# AUX_AIODIO register map
Vendor: Texas Instruments
Peripheral module from a debugger description file (folder CC2652).
Registers are 32-bit, access per field, reset 0x0 unless marked. A register's access mark holds for its fields unless they carry their own. Offsets are as the file gives them; lines under a group give offsets from that group; [hi:lo] are bit positions; {n}, {i} and the like mark numbered series; 'fields as' and 'values as' point back to an identical list; <NAME> marks a mode.

## AUX_AIODIO — AUX Analog Digital Input Output Controller (AUX_AIODIO) controls the general purpose input output pins of the AUX domain. These pins are referenced as AUXIO and can: - be connected to analog AUX modules, such as comparators and ADC. - be used by AUX_SCE. - connect to AUX_SPIM SCLK, MISO and MOSI signals. - connect to the asynchronous AUX event bus. Enabled digital inputs are synchronized at SCE clock rate. Note that the IO mapping in the AUX domain is different from the IO mapping in the MCU domain. This means that AUXIO[n] does not map to DIO[n]. AUXIO-DIO remapping is handled by Sensor Controller Studio.
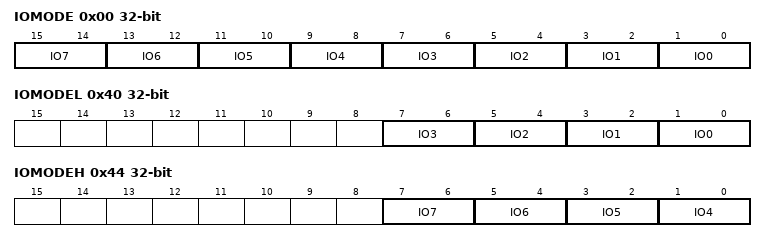
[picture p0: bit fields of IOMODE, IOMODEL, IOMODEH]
0x00 IOMODE — Input Output Mode This register controls pull-up, pull-down, and output mode for AUXIO that are controlled by instance i of AUX_AIODIO. Hence, in formulas below i = 0 for AUX_AIODIO0, i = 1 for AUX_AIODIO1, and so forth.
  [15:14] IO7 rw — Selects mode for AUXIO[8i+7].
    3=OPEN_SOURCE (Open-Source Mode: When IOPOE bit 7 is 0: - If GPIODOUT bit 7 is 0: AUXIO[8i+7] is tri-stated or pulled. This depends on IOC:IOCFGn.PULL_CTL. - If GPIODOUT bit 7 is 1: AUXIO[8i+7] is driven high. When IOPOE bit 7 is 1: - If signal selected by IO7PSEL.SRC is 0: AUXIO[8i+7] is tri-stated or pulled. This depends on IOC:IOCFGn.PULL_CTL. - If signal selected by IO7PSEL.SRC is 1: AUXIO[8i+7] is driven high.); 2=OPEN_DRAIN (Open-Drain Mode: When IOPOE bit 7 is 0: - If GPIODOUT bit 7 is 0: AUXIO[8i+7] is driven low. - If GPIODOUT bit 7 is 1: AUXIO[8i+7] is tri-stated or pulled. This depends on IOC:IOCFGn.PULL_CTL. When IOPOE bit 7 is 1: - If signal selected by IO7PSEL.SRC is 0: AUXIO[8i+7] is driven low. - If signal selected by IO7PSEL.SRC is 1: AUXIO[8i+7] is tri-stated or pulled. This depends on IOC:IOCFGn.PULL_CTL.); 1=IN (Input Mode: When GPIODIE bit 7 is 0: AUXIO[8i+7] is enabled for analog signal transfer. When GPIODIE bit 7 is 1: AUXIO[8i+7] is enabled for digital input.); 0=OUT (Output Mode: When IOPOE bit 7 is 0: GPIODOUT bit 7 drives AUXIO[8i+7]. When IOPOE bit 7 is 1: The signal selected by IO7PSEL.SRC drives AUXIO[8i+7].)
  [13:12] IO6 rw — Selects mode for AUXIO[8i+6].
    3=OPEN_SOURCE (Open-Source Mode: When IOPOE bit 6 is 0: - If GPIODOUT bit 6 is 0: AUXIO[8i+6] is tri-stated or pulled. This depends on IOC:IOCFGn.PULL_CTL. - If GPIODOUT bit 6 is 1: AUXIO[8i+6] is driven high. When IOPOE bit 6 is 1: - If signal selected by IO6PSEL.SRC is 0: AUXIO[8i+6] is tri-stated or pulled. This depends on IOC:IOCFGn.PULL_CTL. - If signal selected by IO6PSEL.SRC is 1: AUXIO[8i+6] is driven high.); 2=OPEN_DRAIN (Open-Drain Mode: When IOPOE bit 6 is 0: - If GPIODOUT bit 6 is 0: AUXIO[8i+6] is driven low. - If GPIODOUT bit 6 is 1: AUXIO[8i+6] is tri-stated or pulled. This depends on IOC:IOCFGn.PULL_CTL. When IOPOE bit 6 is 1: - If signal selected by IO6PSEL.SRC is 0: AUXIO[8i+6] is driven low. - If signal selected by IO6PSEL.SRC is 1: AUXIO[8i+6] is tri-stated or pulled. This depends on IOC:IOCFGn.PULL_CTL.); 1=IN (Input Mode: When GPIODIE bit 6 is 0: AUXIO[8i+6] is enabled for analog signal transfer. When GPIODIE bit 6 is 1: AUXIO[8i+6] is enabled for digital input.); 0=OUT (Output Mode: When IOPOE bit 6 is 0: GPIODOUT bit 6 drives AUXIO[8i+6]. When IOPOE bit 6 is 1: The signal selected by IO6PSEL.SRC drives AUXIO[8i+6].)
  [11:10] IO5 rw — Selects mode for AUXIO[8i+5].
    3=OPEN_SOURCE (Open-Source Mode: When IOPOE bit 5 is 0: - If GPIODOUT bit 5 is 0: AUXIO[8i+5] is tri-stated or pulled. This depends on IOC:IOCFGn.PULL_CTL. - If GPIODOUT bit 5 is 1: AUXIO[8i+5] is driven high. When IOPOE bit 5 is 1: - If signal selected by IO5PSEL.SRC is 0: AUXIO[8i+5] is tri-stated or pulled. This depends on IOC:IOCFGn.PULL_CTL. - If signal selected by IO5PSEL.SRC is 1: AUXIO[8i+5] is driven high.); 2=OPEN_DRAIN (Open-Drain Mode: When IOPOE bit 5 is 0: - If GPIODOUT bit 5 is 0: AUXIO[8i+5] is driven low. - If GPIODOUT bit 5 is 1: AUXIO[8i+5] is tri-stated or pulled. This depends on IOC:IOCFGn.PULL_CTL. When IOPOE bit 5 is 1: - If signal selected by IO5PSEL.SRC is 0: AUXIO[8i+5] is driven low. - If signal selected by IO5PSEL.SRC is 1: AUXIO[8i+5] is tri-stated or pulled. This depends on IOC:IOCFGn.PULL_CTL.); 1=IN (Input Mode: When GPIODIE bit 5 is 0: AUXIO[8i+5] is enabled for analog signal transfer. When GPIODIE bit 5 is 1: AUXIO[8i+5] is enabled for digital input.); 0=OUT (Output Mode: When IOPOE bit 5 is 0: GPIODOUT bit 5 drives AUXIO[8i+5]. When IOPOE bit 5 is 1: The signal selected by IO5PSEL.SRC drives AUXIO[8i+5].)
  [9:8] IO4 rw — Selects mode for AUXIO[8i+4].
    3=OPEN_SOURCE (Open-Source Mode: When IOPOE bit 4 is 0: - If GPIODOUT bit 4 is 0: AUXIO[8i+4] is tri-stated or pulled. This depends on IOC:IOCFGn.PULL_CTL. - If GPIODOUT bit 4 is 1: AUXIO[8i+4] is driven high. When IOPOE bit 4 is 1: - If signal selected by IO4PSEL.SRC is 0: AUXIO[8i+4] is tri-stated or pulled. This depends on IOC:IOCFGn.PULL_CTL. - If signal selected by IO4PSEL.SRC is 1: AUXIO[8i+4] is driven high.); 2=OPEN_DRAIN (Open-Drain Mode: When IOPOE bit 4 is 0: - If GPIODOUT bit 4 is 0: AUXIO[8i+4] is driven low. - If GPIODOUT bit 4 is 1: AUXIO[8i+4] is tri-stated or pulled. This depends on IOC:IOCFGn.PULL_CTL. When IOPOE bit 4 is 1: - If signal selected by IO4PSEL.SRC is 0: AUXIO[8i+4] is driven low. - If signal selected by IO4PSEL.SRC is 1: AUXIO[8i+4] is tri-stated or pulled. This depends on IOC:IOCFGn.PULL_CTL.); 1=IN (Input Mode: When GPIODIE bit 4 is 0: AUXIO[8i+4] is enabled for analog signal transfer. When GPIODIE bit 4 is 1: AUXIO[8i+4] is enabled for digital input.); 0=OUT (Output Mode: When IOPOE bit 4 is 0: GPIODOUT bit 4 drives AUXIO[8i+4]. When IOPOE bit 4 is 1: The signal selected by IO4PSEL.SRC drives AUXIO[8i+4].)
  [7:6] IO3 rw — Selects mode for AUXIO[8i+3].
    3=OPEN_SOURCE (Open-Source Mode: When IOPOE bit 3 is 0: - If GPIODOUT bit 3 is 0: AUXIO[8i+3] is tri-stated or pulled. This depends on IOC:IOCFGn.PULL_CTL. - If GPIODOUT bit 3 is 1: AUXIO[8i+3] is driven high. When IOPOE bit 3 is 1: - If signal selected by IO3PSEL.SRC is 0: AUXIO[8i+3] is tri-stated or pulled. This depends on IOC:IOCFGn.PULL_CTL. - If signal selected by IO3PSEL.SRC is 1: AUXIO[8i+3] is driven high.); 2=OPEN_DRAIN (Open-Drain Mode: When IOPOE bit 3 is 0: - If GPIODOUT bit 3 is 0: AUXIO[8i+3] is driven low. - If GPIODOUT bit 3 is 1: AUXIO[8i+3] is tri-stated or pulled. This depends on IOC:IOCFGn.PULL_CTL. When IOPOE bit 3 is 1: - If signal selected by IO3PSEL.SRC is 0: AUXIO[8i+3] is driven low. - If signal selected by IO3PSEL.SRC is 1: AUXIO[8i+3] is tri-stated or pulled. This depends on IOC:IOCFGn.PULL_CTL.); 1=IN (Input Mode: When GPIODIE bit 3 is 0: AUXIO[8i+3] is enabled for analog signal transfer. When GPIODIE bit 3 is 1: AUXIO[8i+3] is enabled for digital input.); 0=OUT (Output Mode: When IOPOE bit 3 is 0: GPIODOUT bit 3 drives AUXIO[8i+3]. When IOPOE bit 3 is 1: The signal selected by IO3PSEL.SRC drives AUXIO[8i+3].)
  [5:4] IO2 rw — Select mode for AUXIO[8i+2].
    3=OPEN_SOURCE (Open-Source Mode: When IOPOE bit 2 is 0: - If GPIODOUT bit 2 is 0: AUXIO[8i+2] is tri-stated or pulled. This depends on IOC:IOCFGn.PULL_CTL. - If GPIODOUT bit 2 is 1: AUXIO[8i+2] is driven high. When IOPOE bit 2 is 1: - If signal selected by IO2PSEL.SRC is 0: AUXIO[8i+2] is tri-stated or pulled. This depends on IOC:IOCFGn.PULL_CTL. - If signal selected by IO2PSEL.SRC is 1: AUXIO[8i+2] is driven high.); 2=OPEN_DRAIN (Open-Drain Mode: When IOPOE bit 2 is 0: - If GPIODOUT bit 2 is 0: AUXIO[8i+2] is driven low. - If GPIODOUT bit 2 is 1: AUXIO[8i+2] is tri-stated or pulled. This depends on IOC:IOCFGn.PULL_CTL. When IOPOE bit 2 is 1: - If signal selected by IO2PSEL.SRC is 0: AUXIO[8i+2] is driven low. - If signal selected by IO2PSEL.SRC is 1: AUXIO[8i+2] is tri-stated or pulled. This depends on IOC:IOCFGn.PULL_CTL.); 1=IN (Input Mode: When GPIODIE bit 2 is 0: AUXIO[8i+2] is enabled for analog signal transfer. When GPIODIE bit 2 is 1: AUXIO[8i+2] is enabled for digital input.); 0=OUT (Output Mode: When IOPOE bit 2 is 0: GPIODOUT bit 2 drives AUXIO[8i+2]. When IOPOE bit 2 is 1: The signal selected by IO2PSEL.SRC drives AUXIO[8i+2].)
  [3:2] IO1 rw — Select mode for AUXIO[8i+1].
    3=OPEN_SOURCE (Open-Source Mode: When IOPOE bit 1 is 0: - If GPIODOUT bit 1 is 0: AUXIO[8i+1] is tri-stated or pulled. This depends on IOC:IOCFGn.PULL_CTL. - If GPIODOUT bit 1 is 1: AUXIO[8i+1] is driven high. When IOPOE bit 1 is 1: - If signal selected by IO1PSEL.SRC is 0: AUXIO[8i+1] is tri-stated or pulled. This depends on IOC:IOCFGn.PULL_CTL. - If signal selected by IO1PSEL.SRC is 1: AUXIO[8i+1] is driven high.); 2=OPEN_DRAIN (Open-Drain Mode: When IOPOE bit 1 is 0: - If GPIODOUT bit 1 is 0: AUXIO[8i+1] is driven low. - If GPIODOUT bit 1 is 1: AUXIO[8i+1] is tri-stated or pulled. This depends on IOC:IOCFGn.PULL_CTL. When IOPOE bit 1 is 1: - If signal selected by IO1PSEL.SRC is 0: AUXIO[8i+1] is driven low. - If signal selected by IO1PSEL.SRC is 1: AUXIO[8i+1] is tri-stated or pulled. This depends on IOC:IOCFGn.PULL_CTL.); 1=IN (Input Mode: When GPIODIE bit 1 is 0: AUXIO[8i+1] is enabled for analog signal transfer. When GPIODIE bit 1 is 1: AUXIO[8i+1] is enabled for digital input.); 0=OUT (Output Mode: When IOPOE bit 1 is 0: GPIODOUT bit 1 drives AUXIO[8i+1]. When IOPOE bit 1 is 1: The signal selected by IO1PSEL.SRC drives AUXIO[8i+1].)
  [1:0] IO0 rw — Select mode for AUXIO[8i+0].
    3=OPEN_SOURCE (Open-Source Mode: When IOPOE bit 0 is 0: - If GPIODOUT bit 0 is 0: AUXIO[8i+0] is tri-stated or pulled. This depends on IOC:IOCFGn.PULL_CTL. - If GPIODOUT bit 0 is 1: AUXIO[8i+0] is driven high. When IOPOE bit 0 is 1: - If signal selected by IO0PSEL.SRC is 0: AUXIO[8i+0] is tri-stated or pulled. This depends on IOC:IOCFGn.PULL_CTL. - If signal selected by IO0PSEL.SRC is 1: AUXIO[8i+0] is driven high.); 2=OPEN_DRAIN (Open-Drain Mode: When IOPOE bit 0 is 0: - If GPIODOUT bit 0 is 0: AUXIO[8i+0] is driven low. - If GPIODOUT bit 0 is 1: AUXIO[8i+0] is tri-stated or pulled. This depends on IOC:IOCFGn.PULL_CTL. When IOPOE bit 0 is 1: - If signal selected by IO0PSEL.SRC is 0: AUXIO[8i+0] is driven low. - If signal selected by IO0PSEL.SRC is 1: AUXIO[8i+0] is tri-stated or pulled. This depends on IOC:IOCFGn.PULL_CTL.); 1=IN (Input Mode: When GPIODIE bit 0 is 0: AUXIO[8i+0] is enabled for analog signal transfer. When GPIODIE bit 0 is 1: AUXIO[8i+0] is enabled for digital input.); 0=OUT (Output Mode: When IOPOE bit 0 is 0: GPIODOUT bit 0 drives AUXIO[8i+0]. When IOPOE bit 0 is 1: The signal selected by IO0PSEL.SRC drives AUXIO[8i+0].)
0x04 GPIODIE — General Purpose Input Output Digital Input Enable This register controls input buffers for AUXIO that are controlled by instance i of AUX_AIODIO. Hence, in formulas below i = 0 for AUX_AIODIO0, i = 1 for AUX_AIODIO1, and so forth.
  [7:0] IO7_0 rw — Write 1 to bit index n in this bit vector to enable digital input buffer for AUXIO[8i+n]. Write 0 to bit index n in this bit vector to disable digital input buffer for AUXIO[8i+n]. You must enable the digital input buffer for AUXIO[8i+n] to read the pin value in GPIODIN. You must disable the digital input buffer for analog input or pins that float to avoid current leakage.
0x08 IOPOE — Input Output Peripheral Output Enable This register selects the output source for AUXIO that are controlled by instance i of AUX_AIODIO. Hence, in formulas below i = 0 for AUX_AIODIO0, i = 1 for AUX_AIODIO1, and so forth.
  [7:0] IO7_0 rw — Write 1 to bit index n in this bit vector to configure AUXIO[8i+n] to be driven from source given in [IOnPSEL.*]. Write 0 to bit index n in this bit vector to configure AUXIO[8i+n] to be driven from bit n in GPIODOUT.
0x0C GPIODOUT — General Purpose Input Output Data Out The output data register is used to set data on AUXIO that are controlled by instance i of AUX_AIODIO. Hence, in formulas below i = 0 for AUX_AIODIO0, i = 1 for AUX_AIODIO1, and so forth.
  [7:0] IO7_0 rw — Write 1 to bit index n in this bit vector to set AUXIO[8i+n]. Write 0 to bit index n in this bit vector to clear AUXIO[8i+n]. You must clear bit n in IOPOE to connect bit n in this bit vector to AUXIO[8i+n].
0x10 GPIODIN ro — General Purpose Input Output Data In This register provides synchronized input data for AUXIO that are controlled by instance i of AUX_AIODIO. Hence, in formulas below i = 0 for AUX_AIODIO0, i = 1 for AUX_AIODIO1, and so forth
  [7:0] IO7_0 — Bit n in this bit vector contains the value for AUXIO[8i+n] when GPIODIE bit n is set. Otherwise, bit n is read as 0.
0x14 GPIODOUTSET — General Purpose Input Output Data Out Set Set bits in GPIODOUT in instance i of AUX_AIODIO. Hence, in formulas below i = 0 for AUX_AIODIO0, i = 1 for AUX_AIODIO1, and so forth.
  [7:0] IO7_0 rw — Write 1 to bit index n in this bit vector to set GPIODOUT bit n. Read value is 0.
0x18 GPIODOUTCLR — General Purpose Input Output Data Out Clear Clear bits in GPIODOUT instance i of AUX_AIODIO. Hence, in formulas below i = 0 for AUX_AIODIO0, i = 1 for AUX_AIODIO1, and so forth.
  [7:0] IO7_0 rw — Write 1 to bit index n in this bit vector to clear GPIODOUT bit n. Read value is 0.
0x1C GPIODOUTTGL — General Purpose Input Output Data Out Toggle Toggle bits in GPIODOUT in instance i of AUX_AIODIO. Hence, in formulas below i = 0 for AUX_AIODIO0, i = 1 for AUX_AIODIO1, and so forth.
  [7:0] IO7_0 rw — Write 1 to bit index n in this bit vector to toggle GPIODOUT bit n. Read value is 0.
0x20 IO0PSEL — Input Output 0 Peripheral Select This register selects a peripheral signal that connects to AUXIO[8i+0] when IOPOE bit 0 is 1. To avoid glitches on AUXIO[8i+0] you must configure this register while IOPOE bit 0 is 0. In the formulas i = 0 for AUX_AIODIO0, i = 1 for AUX_AIODIO1, and so forth.
  [2:0] SRC rw — Select a peripheral signal that connects to AUXIO[8i+0] when IOPOE bit 0 is set.
    7=AUX_TIMER2_PULSE (Peripheral output mux selects asynchronous version of AUX_EVCTL:EVSTAT3.AUX_TIMER2_PULSE.); {v}=AUX_TIMER2_EV{v-3} (Peripheral output mux selects asynchronous version of AUX_EVCTL:EVSTAT3.AUX_TIMER2_EV{v-3}.) (v=3..6); 2=AUX_SPIM_MOSI (Peripheral output mux selects AUX_SPIM MOSI.); 1=AUX_SPIM_SCLK (Peripheral output mux selects AUX_SPIM SCLK.); 0=AUX_EV_OBS (Peripheral output mux selects event selected by AUX_EVCTL:EVOBSCFG)
0x24 IO1PSEL — Input Output 1 Peripheral Select This register selects a peripheral signal that connects to AUXIO[8i+1] when IOPOE bit 1 is 1. To avoid glitches on AUXIO[8i+1] you must configure this register while IOPOE bit 1 is 0. In the formulas i = 0 for AUX_AIODIO0, i = 1 for AUX_AIODIO1, and so forth.
  [2:0] SRC rw — Select a peripheral signal that connects to AUXIO[8i+1] when IOPOE bit 1 is set.
    values as IO0PSEL.SRC
0x28 IO2PSEL — Input Output 2 Peripheral Select This register selects a peripheral signal that connects to AUXIO[8i+2] when IOPOE bit 2 is 1. To avoid glitches on AUXIO[8i+2] you must configure this register while IOPOE bit 2 is 0. In the formulas i = 0 for AUX_AIODIO0, i = 1 for AUX_AIODIO1, and so forth.
  [2:0] SRC rw — Select a peripheral signal that connects to AUXIO[8i+2] when IOPOE bit 2 is set.
    values as IO0PSEL.SRC
0x2C IO3PSEL — Input Output 3 Peripheral Select This register selects a peripheral signal that connects to AUXIO[8i+3] when IOPOE bit 3 is 1. To avoid glitches on AUXIO[8i+3] you must configure this register while IOPOE bit 3 is 0. In the formulas i = 0 for AUX_AIODIO0, i = 1 for AUX_AIODIO1, and so forth.
  [2:0] SRC rw — Select a peripheral signal that connects to AUXIO[8i+3] when IOPOE bit 3 is set.
    values as IO0PSEL.SRC
0x30 IO4PSEL — Input Output 4 Peripheral Select This register selects a peripheral signal that connects to AUXIO[8i+4] when IOPOE bit 4 is 1. To avoid glitches on AUXIO[8i+4] you must configure this register while IOPOE bit 4 is 0. In the formulas i = 0 for AUX_AIODIO0, i = 1 for AUX_AIODIO1, and so forth.
  [2:0] SRC rw — Select a peripheral signal that connects to AUXIO[8i+4] when IOPOE bit 4 is set.
    values as IO0PSEL.SRC
0x34 IO5PSEL — Input Output 5 Peripheral Select This register selects a peripheral signal that connects to AUXIO[8i+5] when IOPOE bit 5 is 1. To avoid glitches on AUXIO[8i+5] you must configure this register while IOPOE bit 5 is 0. In the formulas i = 0 for AUX_AIODIO0, i = 1 for AUX_AIODIO1, and so forth.
  [2:0] SRC rw — Select a peripheral signal that connects to AUXIO[8i+5] when IOPOE bit 5 is set.
    values as IO0PSEL.SRC
0x38 IO6PSEL — Input Output 6 Peripheral Select This register selects a peripheral signal that connects to AUXIO[8i+6] when IOPOE bit 6 is 1. To avoid glitches on AUXIO[8i+6] you must configure this register while IOPOE bit 6 is 0. In the formulas i = 0 for AUX_AIODIO0, i = 1 for AUX_AIODIO1, and so forth.
  [2:0] SRC rw — Select a peripheral signal that connects to AUXIO[8i+6] when IOPOE bit 6 is set.
    values as IO0PSEL.SRC
0x3C IO7PSEL — Input Output 7 Peripheral Select This register selects a peripheral signal that connects to AUXIO[8i+7] when IOPOE bit 7 is 1. To avoid glitches on AUXIO[8i+7] you must configure this register while IOPOE bit 7 is 0. In the formulas i = 0 for AUX_AIODIO0, i = 1 for AUX_AIODIO1, and so forth.
  [2:0] SRC rw — Select a peripheral signal that connects to AUXIO[8i+7] when IOPOE bit 7 is set.
    values as IO0PSEL.SRC
0x40 IOMODEL — Input Output Mode Low This is an alias register for IOMODE.IO0 thru IOMODE.IO3.
  [2n+1:2n] IO{n} rw (n=0..3) — See IOMODE.IO{n}.
0x44 IOMODEH — Input Output Mode High This is an alias register for IOMODE.IO4 thru IOMODE.IO7.
  [2n-7:2n-8] IO{n} rw (n=4..7) — See IOMODE.IO{n}.
